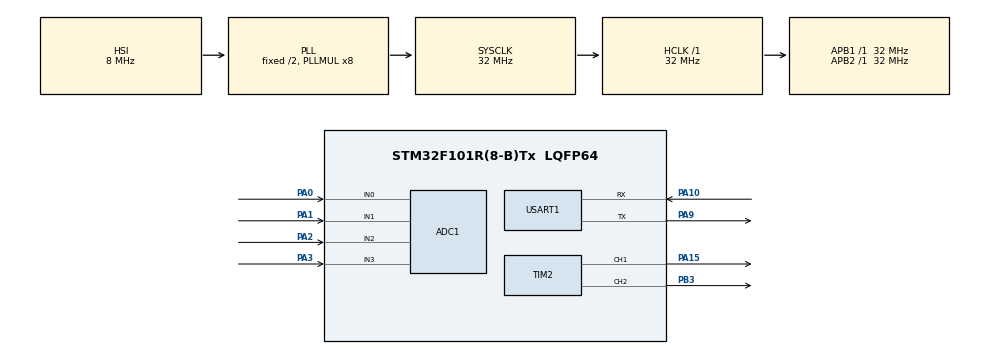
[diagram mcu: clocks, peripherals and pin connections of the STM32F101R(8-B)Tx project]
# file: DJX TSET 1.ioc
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ADC1.Channel-0\#ChannelRegularConversion=ADC_CHANNEL_0
ADC1.NbrOfConversionFlag=1
ADC1.Rank-0\#ChannelRegularConversion=1
ADC1.SamplingTime-0\#ChannelRegularConversion=ADC_SAMPLETIME_1CYCLE_5
ADC1.master=1
Dma.ADC1.0.Direction=DMA_PERIPH_TO_MEMORY
Dma.ADC1.0.Instance=DMA1_Channel1
Dma.ADC1.0.MemDataAlignment=DMA_MDATAALIGN_HALFWORD
Dma.ADC1.0.MemInc=DMA_MINC_ENABLE
Dma.ADC1.0.Mode=DMA_NORMAL
Dma.ADC1.0.PeriphDataAlignment=DMA_PDATAALIGN_HALFWORD
Dma.ADC1.0.PeriphInc=DMA_PINC_DISABLE
Dma.ADC1.0.Priority=DMA_PRIORITY_LOW
Dma.Request0=ADC1
FREERTOS.Tasks01=defaultTask,0,128,StartDefaultTask,Default,NULL,Dynamic,NULL,NULL;myTask02,0,128,StartTask02,Default,NULL,Dynamic,NULL,NULL
FREERTOS.configUSE_PREEMPTION=1
Mcu.Family=STM32F1
Mcu.Name=STM32F101R(8-B)Tx
Mcu.Package=LQFP64
NVIC.DMA1_Channel1_IRQn=true\:5\:0\:false\:false\:true\:true\:false\:true
NVIC.PriorityGroup=NVIC_PRIORITYGROUP_4
PA0-WKUP.Signal=ADCx_IN0
PA1.Signal=ADCx_IN1
PA10.Mode=Asynchronous
PA10.Signal=USART1_RX
PA15.Signal=S_TIM2_CH1_ETR
PA2.Signal=ADCx_IN2
PA3.Signal=ADCx_IN3
PA9.Mode=Asynchronous
PA9.Signal=USART1_TX
PB3.Signal=S_TIM2_CH2
ProjectManager.HeapSize=0x200
ProjectManager.StackSize=0x400
ProjectManager.TargetToolchain=MDK-ARM V5
RCC.AHBFreq_Value=32000000
RCC.APB1Freq_Value=32000000
RCC.APB1TimFreq_Value=32000000
RCC.APB2Freq_Value=32000000
RCC.HCLKFreq_Value=32000000
RCC.PLLMUL=RCC_PLL_MUL8
RCC.SYSCLKFreq_VALUE=32000000
RCC.SYSCLKSource=RCC_SYSCLKSOURCE_PLLCLK
SH.ADCx_IN0.0=ADC1_IN0,IN0
SH.ADCx_IN1.0=ADC1_IN1,IN1
SH.ADCx_IN2.0=ADC1_IN2,IN2
SH.ADCx_IN3.0=ADC1_IN3,IN3
SH.S_TIM2_CH1_ETR.0=TIM2_CH1,PWM Generation1 CH1
SH.S_TIM2_CH2.0=TIM2_CH2,PWM Generation2 CH2
TIM2.Channel-PWM\ Generation1\ CH1=TIM_CHANNEL_1
TIM2.Channel-PWM\ Generation2\ CH2=TIM_CHANNEL_2
USART1.VirtualMode=VM_ASYNC
VP_FREERTOS_VS_CMSIS_V1.Mode=CMSIS_V1
VP_SYS_VS_ND.Mode=No_Debug
board=custom

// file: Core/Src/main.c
/* USER CODE BEGIN Header */
/**
  ******************************************************************************
  * @file           : main.c
  * @brief          : Main program body
  ******************************************************************************
  * @attention
  *
  * <h2><center>&copy; Copyright (c) 2019 STMicroelectronics.
  * All rights reserved.</center></h2>
  *
  * This software component is licensed by ST under Ultimate Liberty license
  * SLA0044, the "License"; You may not use this file except in compliance with
  * the License. You may obtain a copy of the License at:
  *                             www.st.com/SLA0044
  *
  ******************************************************************************
  */
/* USER CODE END Header */

#include "main.h"
#include "cmsis_os.h"
#include "stdio.h"

ADC_HandleTypeDef hadc1;
DMA_HandleTypeDef hdma_adc1;

TIM_HandleTypeDef htim2;

UART_HandleTypeDef huart1;

osThreadId defaultTaskHandle;
osThreadId myTask02Handle;

void SystemClock_Config(void);
static void MX_GPIO_Init(void);
static void MX_DMA_Init(void);
static void MX_ADC1_Init(void);
static void MX_TIM2_Init(void);
static void MX_USART1_UART_Init(void);
void StartDefaultTask(void const * argument);
void StartTask02(void const * argument);

/* USER CODE BEGIN 0 */
uint32_t ADC_VALUE[4]={0};
#ifdef _GNUC_
#define PUTCHAR_PROTOTYPE int __io_putchar(int ch)
#else
#define PUTCHAR_PROTOTYPE int fputc(int ch, FILE *f)
#endif
PUTCHAR_PROTOTYPE
{
    HAL_UART_Transmit(&huart1,(uint8_t *)&ch,1,0xffff);
    return ch;
}

/* USER CODE END 0 */

int main(void)
{

  /* MCU Configuration--------------------------------------------------------*/

  /* Reset of all peripherals, Initializes the Flash interface and the Systick. */
  HAL_Init();

  /* Configure the system clock */
  SystemClock_Config();

  /* Initialize all configured peripherals */
  MX_GPIO_Init();
  MX_DMA_Init();
  MX_ADC1_Init();
  MX_TIM2_Init();
  MX_USART1_UART_Init();

  /* Create the thread(s) */
  /* definition and creation of defaultTask */
  osThreadDef(defaultTask, StartDefaultTask, osPriorityNormal, 0, 128);
  defaultTaskHandle = osThreadCreate(osThread(defaultTask), NULL);

  /* definition and creation of myTask02 */
  osThreadDef(myTask02, StartTask02, osPriorityNormal, 0, 128);
  myTask02Handle = osThreadCreate(osThread(myTask02), NULL);

  /* Start scheduler */
  osKernelStart();

  /* We should never get here as control is now taken by the scheduler */

  /* Infinite loop */
  while (1)
  {

  }
}

void SystemClock_Config(void)
{
  RCC_OscInitTypeDef RCC_OscInitStruct = {0};
  RCC_ClkInitTypeDef RCC_ClkInitStruct = {0};
  RCC_PeriphCLKInitTypeDef PeriphClkInit = {0};

  /** Initializes the CPU, AHB and APB busses clocks
  */
  RCC_OscInitStruct.OscillatorType = RCC_OSCILLATORTYPE_HSI;
  RCC_OscInitStruct.HSIState = RCC_HSI_ON;
  RCC_OscInitStruct.HSICalibrationValue = RCC_HSICALIBRATION_DEFAULT;
  RCC_OscInitStruct.PLL.PLLState = RCC_PLL_ON;
  RCC_OscInitStruct.PLL.PLLSource = RCC_PLLSOURCE_HSI_DIV2;
  RCC_OscInitStruct.PLL.PLLMUL = RCC_PLL_MUL8;
  if (HAL_RCC_OscConfig(&RCC_OscInitStruct) != HAL_OK)
  {
    Error_Handler();
  }
  /** Initializes the CPU, AHB and APB busses clocks
  */
  RCC_ClkInitStruct.ClockType = RCC_CLOCKTYPE_HCLK|RCC_CLOCKTYPE_SYSCLK
                              |RCC_CLOCKTYPE_PCLK1|RCC_CLOCKTYPE_PCLK2;
  RCC_ClkInitStruct.SYSCLKSource = RCC_SYSCLKSOURCE_PLLCLK;
  RCC_ClkInitStruct.AHBCLKDivider = RCC_SYSCLK_DIV1;
  RCC_ClkInitStruct.APB1CLKDivider = RCC_HCLK_DIV1;
  RCC_ClkInitStruct.APB2CLKDivider = RCC_HCLK_DIV1;

  if (HAL_RCC_ClockConfig(&RCC_ClkInitStruct, FLASH_LATENCY_1) != HAL_OK)
  {
    Error_Handler();
  }
  PeriphClkInit.PeriphClockSelection = RCC_PERIPHCLK_ADC;
  PeriphClkInit.AdcClockSelection = RCC_ADCPCLK2_DIV2;
  if (HAL_RCCEx_PeriphCLKConfig(&PeriphClkInit) != HAL_OK)
  {
    Error_Handler();
  }
}

static void MX_ADC1_Init(void)
{

  ADC_ChannelConfTypeDef sConfig = {0};

  /** Common config
  */
  hadc1.Instance = ADC1;
  hadc1.Init.ScanConvMode = ADC_SCAN_DISABLE;
  hadc1.Init.ContinuousConvMode = DISABLE;
  hadc1.Init.DiscontinuousConvMode = DISABLE;
  hadc1.Init.ExternalTrigConv = ADC_SOFTWARE_START;
  hadc1.Init.DataAlign = ADC_DATAALIGN_RIGHT;
  hadc1.Init.NbrOfConversion = 1;
  if (HAL_ADC_Init(&hadc1) != HAL_OK)
  {
    Error_Handler();
  }
  /** Configure Regular Channel
  */
  sConfig.Channel = ADC_CHANNEL_0;
  sConfig.Rank = ADC_REGULAR_RANK_1;
  sConfig.SamplingTime = ADC_SAMPLETIME_1CYCLE_5;
  if (HAL_ADC_ConfigChannel(&hadc1, &sConfig) != HAL_OK)
  {
    Error_Handler();
  }

}

static void MX_TIM2_Init(void)
{

  TIM_MasterConfigTypeDef sMasterConfig = {0};
  TIM_OC_InitTypeDef sConfigOC = {0};

  htim2.Instance = TIM2;
  htim2.Init.Prescaler = 0;
  htim2.Init.CounterMode = TIM_COUNTERMODE_UP;
  htim2.Init.Period = 0;
  htim2.Init.ClockDivision = TIM_CLOCKDIVISION_DIV1;
  htim2.Init.AutoReloadPreload = TIM_AUTORELOAD_PRELOAD_DISABLE;
  if (HAL_TIM_PWM_Init(&htim2) != HAL_OK)
  {
    Error_Handler();
  }
  sMasterConfig.MasterOutputTrigger = TIM_TRGO_RESET;
  sMasterConfig.MasterSlaveMode = TIM_MASTERSLAVEMODE_DISABLE;
  if (HAL_TIMEx_MasterConfigSynchronization(&htim2, &sMasterConfig) != HAL_OK)
  {
    Error_Handler();
  }
  sConfigOC.OCMode = TIM_OCMODE_PWM1;
  sConfigOC.Pulse = 0;
  sConfigOC.OCPolarity = TIM_OCPOLARITY_HIGH;
  sConfigOC.OCFastMode = TIM_OCFAST_DISABLE;
  if (HAL_TIM_PWM_ConfigChannel(&htim2, &sConfigOC, TIM_CHANNEL_1) != HAL_OK)
  {
    Error_Handler();
  }
  if (HAL_TIM_PWM_ConfigChannel(&htim2, &sConfigOC, TIM_CHANNEL_2) != HAL_OK)
  {
    Error_Handler();
  }
  HAL_TIM_MspPostInit(&htim2);

}

static void MX_USART1_UART_Init(void)
{

  huart1.Instance = USART1;
  huart1.Init.BaudRate = 115200;
  huart1.Init.WordLength = UART_WORDLENGTH_8B;
  huart1.Init.StopBits = UART_STOPBITS_1;
  huart1.Init.Parity = UART_PARITY_NONE;
  huart1.Init.Mode = UART_MODE_TX_RX;
  huart1.Init.HwFlowCtl = UART_HWCONTROL_NONE;
  huart1.Init.OverSampling = UART_OVERSAMPLING_16;
  if (HAL_UART_Init(&huart1) != HAL_OK)
  {
    Error_Handler();
  }

}

static void MX_DMA_Init(void)
{
  /* DMA controller clock enable */
  __HAL_RCC_DMA1_CLK_ENABLE();

  /* DMA interrupt init */
  /* DMA1_Channel1_IRQn interrupt configuration */
  HAL_NVIC_SetPriority(DMA1_Channel1_IRQn, 5, 0);
  HAL_NVIC_EnableIRQ(DMA1_Channel1_IRQn);

}

static void MX_GPIO_Init(void)
{

  /* GPIO Ports Clock Enable */
  __HAL_RCC_GPIOA_CLK_ENABLE();
  __HAL_RCC_GPIOB_CLK_ENABLE();

}

void StartDefaultTask(void const * argument)
{

  for(;;)
  {
    osDelay(1);
  }
}

void StartTask02(void const * argument)
{
  /* USER CODE BEGIN StartTask02 */
  /* Infinite loop */
  for(;;)
  {
    HAL_ADC_Start_DMA(&hadc1,ADC_VALUE,4);
    printf("ADC chanel 1 VALUE: %d",ADC_VALUE[0]);
    osDelay(500);
  }
  /* USER CODE END StartTask02 */
}

void Error_Handler(void)
{
}

/************************ (C) COPYRIGHT STMicroelectronics *****END OF FILE****/
